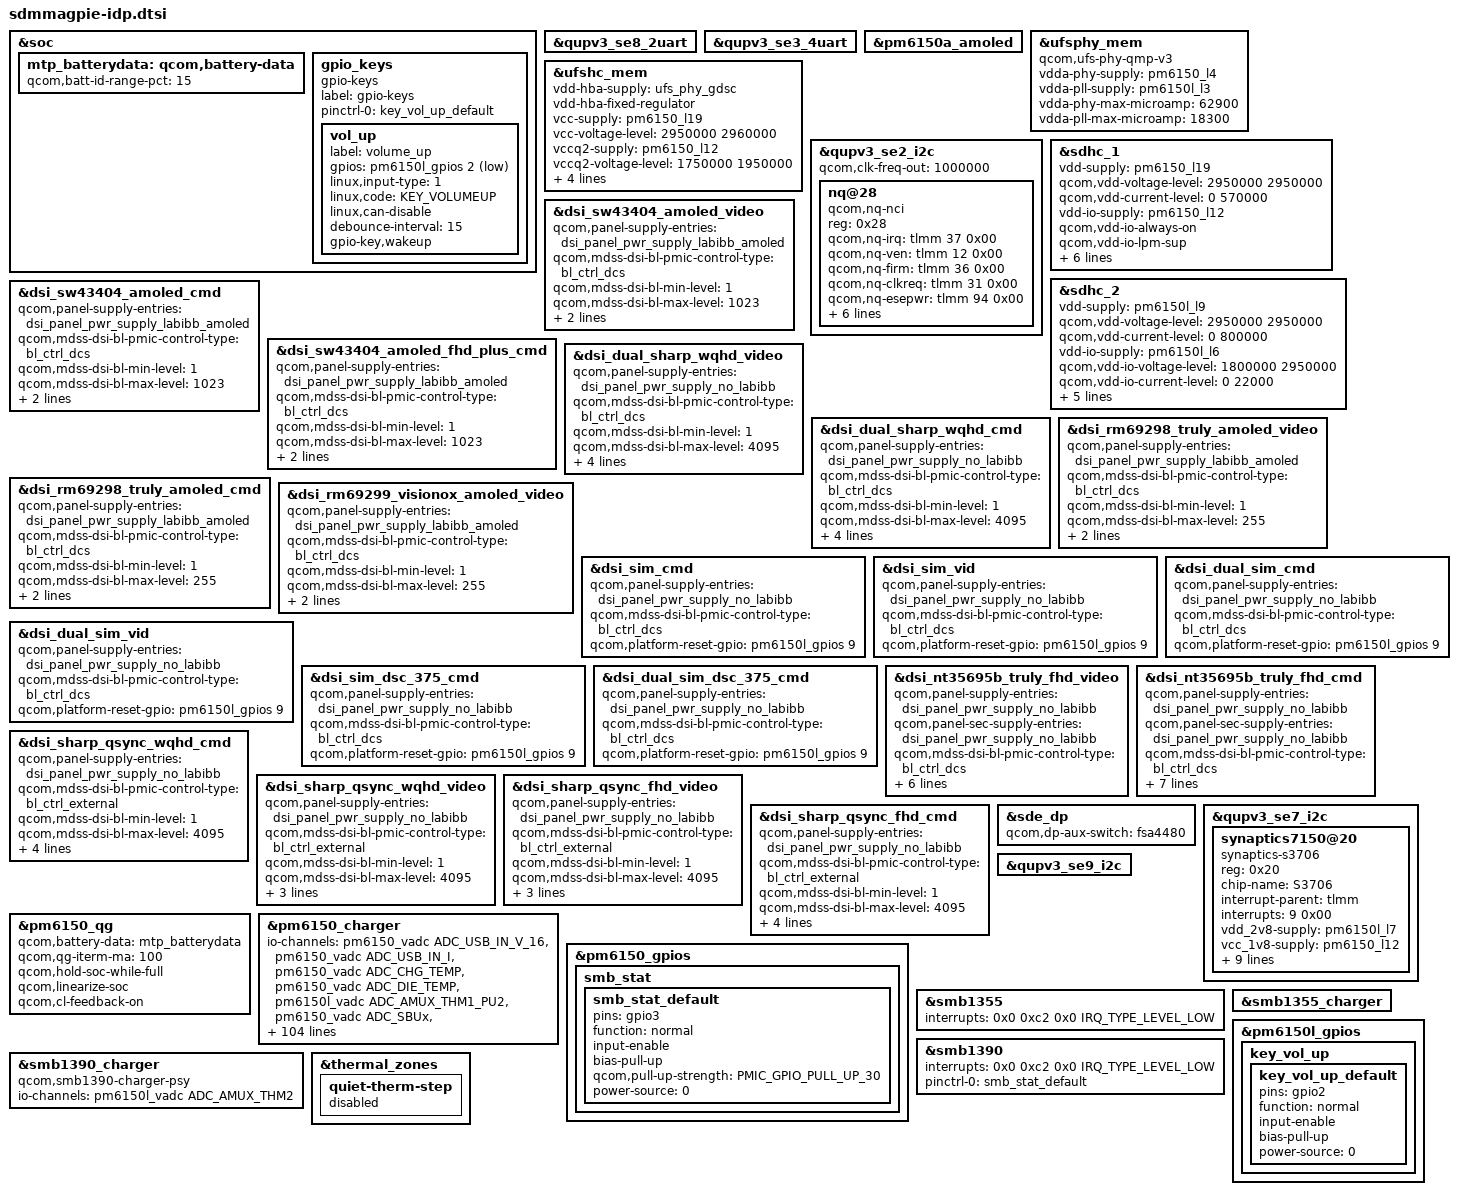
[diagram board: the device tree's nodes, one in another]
/* Copyright (c) 2018-2019, The Linux Foundation. All rights reserved.
 *
 * This program is free software; you can redistribute it and/or modify
 * it under the terms of the GNU General Public License version 2 and
 * only version 2 as published by the Free Software Foundation.
 *
 * This program is distributed in the hope that it will be useful,
 * but WITHOUT ANY WARRANTY; without even the implied warranty of
 * MERCHANTABILITY or FITNESS FOR A PARTICULAR PURPOSE.  See the
 * GNU General Public License for more details.
 */
#include "sdmmagpie-thermal-overlay.dtsi"

#include <dt-bindings/gpio/gpio.h>
#include <dt-bindings/pinctrl/qcom,pmic-gpio.h>
#include <dt-bindings/iio/qcom,spmi-vadc.h>
#include <dt-bindings/input/input.h>
#include "sdmmagpie-sde-display.dtsi"
#include "sdmmagpie-camera-sensor-idp.dtsi"

&soc {
	mtp_batterydata: qcom,battery-data {
		qcom,batt-id-range-pct = <15>;
		#include "qg-batterydata-alium-3600mah.dtsi"
		#include "qg-batterydata-mlp466076-3200mah.dtsi"
	};
};

&qupv3_se8_2uart {
	status = "ok";
};

&qupv3_se3_4uart {
	status = "ok";
};

&pm6150a_amoled {
	status = "ok";
};

&ufsphy_mem {
	compatible = "qcom,ufs-phy-qmp-v3";

	vdda-phy-supply = <&pm6150_l4>; /* 0.88v */
	vdda-pll-supply = <&pm6150l_l3>; /* 1.2v */
	vdda-phy-max-microamp = <62900>;
	vdda-pll-max-microamp = <18300>;

	status = "ok";
};

&ufshc_mem {
	vdd-hba-supply = <&ufs_phy_gdsc>;
	vdd-hba-fixed-regulator;
	vcc-supply = <&pm6150_l19>;
	vcc-voltage-level = <2950000 2960000>;
	vccq2-supply = <&pm6150_l12>;
	vccq2-voltage-level = <1750000 1950000>;
	vcc-max-microamp = <600000>;
	vccq2-max-microamp = <600000>;

	qcom,vddp-ref-clk-supply = <&pm6150l_l3>;
	qcom,vddp-ref-clk-max-microamp = <100>;

	status = "ok";
};

&qupv3_se2_i2c {
	status = "ok";
	qcom,clk-freq-out = <1000000>;
	nq@28 {
		compatible = "qcom,nq-nci";
		reg = <0x28>;
		qcom,nq-irq = <&tlmm 37 0x00>;
		qcom,nq-ven = <&tlmm 12 0x00>;
		qcom,nq-firm = <&tlmm 36 0x00>;
		qcom,nq-clkreq = <&tlmm 31 0x00>;
		qcom,nq-esepwr = <&tlmm 94 0x00>;
		interrupt-parent = <&tlmm>;
		interrupts = <37 0>;
		interrupt-names = "nfc_irq";
		pinctrl-names = "nfc_active", "nfc_suspend";
		pinctrl-0 = <&nfc_int_active &nfc_enable_active
				&nfc_clk_req_active>;
		pinctrl-1 = <&nfc_int_suspend &nfc_enable_suspend
				&nfc_clk_req_suspend>;
	};
};

&sdhc_1 {
	vdd-supply = <&pm6150_l19>;
	qcom,vdd-voltage-level = <2950000 2950000>;
	qcom,vdd-current-level = <0 570000>;

	vdd-io-supply = <&pm6150_l12>;
	qcom,vdd-io-always-on;
	qcom,vdd-io-lpm-sup;
	qcom,vdd-io-voltage-level = <1800000 1800000>;
	qcom,vdd-io-current-level = <0 325000>;

	pinctrl-names = "active", "sleep";
	pinctrl-0 = <&sdc1_clk_on &sdc1_cmd_on &sdc1_data_on &sdc1_rclk_on>;
	pinctrl-1 = <&sdc1_clk_off &sdc1_cmd_off &sdc1_data_off &sdc1_rclk_off>;

	status = "ok";
};

&sdhc_2 {
	vdd-supply = <&pm6150l_l9>;
	qcom,vdd-voltage-level = <2950000 2950000>;
	qcom,vdd-current-level = <0 800000>;

	vdd-io-supply = <&pm6150l_l6>;
	qcom,vdd-io-voltage-level = <1800000 2950000>;
	qcom,vdd-io-current-level = <0 22000>;

	pinctrl-names = "active", "sleep";
	pinctrl-0 = <&sdc2_clk_on  &sdc2_cmd_on &sdc2_data_on &sdc2_cd_on>;
	pinctrl-1 = <&sdc2_clk_off &sdc2_cmd_off &sdc2_data_off &sdc2_cd_off>;

	cd-gpios = <&tlmm 69 GPIO_ACTIVE_LOW>;

	status = "ok";
};

&dsi_sw43404_amoled_video {
	qcom,panel-supply-entries = <&dsi_panel_pwr_supply_labibb_amoled>;
	qcom,mdss-dsi-bl-pmic-control-type = "bl_ctrl_dcs";
	qcom,mdss-dsi-bl-min-level = <1>;
	qcom,mdss-dsi-bl-max-level = <1023>;
	qcom,platform-te-gpio = <&tlmm 10 0>;
	qcom,platform-reset-gpio = <&pm6150l_gpios 9 0>;
};

&dsi_sw43404_amoled_cmd {
	qcom,panel-supply-entries = <&dsi_panel_pwr_supply_labibb_amoled>;
	qcom,mdss-dsi-bl-pmic-control-type = "bl_ctrl_dcs";
	qcom,mdss-dsi-bl-min-level = <1>;
	qcom,mdss-dsi-bl-max-level = <1023>;
	qcom,platform-te-gpio = <&tlmm 10 0>;
	qcom,platform-reset-gpio = <&pm6150l_gpios 9 0>;
};

&dsi_sw43404_amoled_fhd_plus_cmd {
	qcom,panel-supply-entries = <&dsi_panel_pwr_supply_labibb_amoled>;
	qcom,mdss-dsi-bl-pmic-control-type = "bl_ctrl_dcs";
	qcom,mdss-dsi-bl-min-level = <1>;
	qcom,mdss-dsi-bl-max-level = <1023>;
	qcom,platform-te-gpio = <&tlmm 10 0>;
	qcom,platform-reset-gpio = <&pm6150l_gpios 9 0>;
};

&dsi_dual_sharp_wqhd_video {
	qcom,panel-supply-entries = <&dsi_panel_pwr_supply_no_labibb>;
	qcom,mdss-dsi-bl-pmic-control-type = "bl_ctrl_dcs";
	qcom,mdss-dsi-bl-min-level = <1>;
	qcom,mdss-dsi-bl-max-level = <4095>;
	qcom,platform-te-gpio = <&tlmm 10 0>;
	qcom,platform-reset-gpio = <&pm6150l_gpios 9 0>;
	qcom,platform-en-gpio = <&pm6150l_gpios 4 0>;
	qcom,platform-bklight-en-gpio = <&pm6150l_gpios 5 0>;
};

&dsi_dual_sharp_wqhd_cmd {
	qcom,panel-supply-entries = <&dsi_panel_pwr_supply_no_labibb>;
	qcom,mdss-dsi-bl-pmic-control-type = "bl_ctrl_dcs";
	qcom,mdss-dsi-bl-min-level = <1>;
	qcom,mdss-dsi-bl-max-level = <4095>;
	qcom,platform-te-gpio = <&tlmm 10 0>;
	qcom,platform-reset-gpio = <&pm6150l_gpios 9 0>;
	qcom,platform-en-gpio = <&pm6150l_gpios 4 0>;
	qcom,platform-bklight-en-gpio = <&pm6150l_gpios 5 0>;
};

&dsi_rm69298_truly_amoled_video {
	qcom,panel-supply-entries = <&dsi_panel_pwr_supply_labibb_amoled>;
	qcom,mdss-dsi-bl-pmic-control-type = "bl_ctrl_dcs";
	qcom,mdss-dsi-bl-min-level = <1>;
	qcom,mdss-dsi-bl-max-level = <255>;
	qcom,platform-te-gpio = <&tlmm 10 0>;
	qcom,platform-reset-gpio = <&pm6150l_gpios 9 0>;
};

&dsi_rm69298_truly_amoled_cmd {
	qcom,panel-supply-entries = <&dsi_panel_pwr_supply_labibb_amoled>;
	qcom,mdss-dsi-bl-pmic-control-type = "bl_ctrl_dcs";
	qcom,mdss-dsi-bl-min-level = <1>;
	qcom,mdss-dsi-bl-max-level = <255>;
	qcom,platform-te-gpio = <&tlmm 10 0>;
	qcom,platform-reset-gpio = <&pm6150l_gpios 9 0>;
};

&dsi_rm69299_visionox_amoled_video {
	qcom,panel-supply-entries = <&dsi_panel_pwr_supply_labibb_amoled>;
	qcom,mdss-dsi-bl-pmic-control-type = "bl_ctrl_dcs";
	qcom,mdss-dsi-bl-min-level = <1>;
	qcom,mdss-dsi-bl-max-level = <255>;
	qcom,platform-te-gpio = <&tlmm 10 0>;
	qcom,platform-reset-gpio = <&pm6150l_gpios 9 0>;
};

&dsi_sim_cmd {
	qcom,panel-supply-entries = <&dsi_panel_pwr_supply_no_labibb>;
	qcom,mdss-dsi-bl-pmic-control-type = "bl_ctrl_dcs";
	qcom,platform-reset-gpio = <&pm6150l_gpios 9 0>;
};

&dsi_sim_vid {
	qcom,panel-supply-entries = <&dsi_panel_pwr_supply_no_labibb>;
	qcom,mdss-dsi-bl-pmic-control-type = "bl_ctrl_dcs";
	qcom,platform-reset-gpio = <&pm6150l_gpios 9 0>;
};

&dsi_dual_sim_cmd {
	qcom,panel-supply-entries = <&dsi_panel_pwr_supply_no_labibb>;
	qcom,mdss-dsi-bl-pmic-control-type = "bl_ctrl_dcs";
	qcom,platform-reset-gpio = <&pm6150l_gpios 9 0>;
};

&dsi_dual_sim_vid {
	qcom,panel-supply-entries = <&dsi_panel_pwr_supply_no_labibb>;
	qcom,mdss-dsi-bl-pmic-control-type = "bl_ctrl_dcs";
	qcom,platform-reset-gpio = <&pm6150l_gpios 9 0>;
};

&dsi_sim_dsc_375_cmd {
	qcom,panel-supply-entries = <&dsi_panel_pwr_supply_no_labibb>;
	qcom,mdss-dsi-bl-pmic-control-type = "bl_ctrl_dcs";
	qcom,platform-reset-gpio = <&pm6150l_gpios 9 0>;
};

&dsi_dual_sim_dsc_375_cmd {
	qcom,panel-supply-entries = <&dsi_panel_pwr_supply_no_labibb>;
	qcom,mdss-dsi-bl-pmic-control-type = "bl_ctrl_dcs";
	qcom,platform-reset-gpio = <&pm6150l_gpios 9 0>;
};

&dsi_nt35695b_truly_fhd_video {
	qcom,panel-supply-entries = <&dsi_panel_pwr_supply_no_labibb>;
	qcom,panel-sec-supply-entries = <&dsi_panel_pwr_supply_no_labibb>;
	qcom,mdss-dsi-bl-pmic-control-type = "bl_ctrl_dcs";
	qcom,mdss-dsi-sec-bl-pmic-control-type = "bl_ctrl_dcs";
	qcom,platform-reset-gpio = <&pm6150l_gpios 11 0>;
	qcom,platform-sec-reset-gpio = <&pm6150l_gpios 11 0>;
	qcom,platform-en-gpio = <&pm6150l_gpios 4 0>;
	qcom,platform-bklight-en-gpio = <&pm6150l_gpios 5 0>;
};

&dsi_nt35695b_truly_fhd_cmd {
	qcom,panel-supply-entries = <&dsi_panel_pwr_supply_no_labibb>;
	qcom,panel-sec-supply-entries = <&dsi_panel_pwr_supply_no_labibb>;
	qcom,mdss-dsi-bl-pmic-control-type = "bl_ctrl_dcs";
	qcom,mdss-dsi-sec-bl-pmic-control-type = "bl_ctrl_dcs";
	qcom,platform-reset-gpio = <&pm6150l_gpios 11 0>;
	qcom,platform-sec-reset-gpio = <&pm6150l_gpios 11 0>;
	qcom,platform-en-gpio = <&pm6150l_gpios 4 0>;
	qcom,platform-bklight-en-gpio = <&pm6150l_gpios 5 0>;
	qcom,platform-te-gpio = <&tlmm 11 0>;
};

&dsi_sharp_qsync_wqhd_cmd {
	qcom,panel-supply-entries = <&dsi_panel_pwr_supply_no_labibb>;
	qcom,mdss-dsi-bl-pmic-control-type = "bl_ctrl_external";
	qcom,mdss-dsi-bl-min-level = <1>;
	qcom,mdss-dsi-bl-max-level = <4095>;
	qcom,platform-te-gpio = <&tlmm 10 0>;
	qcom,platform-reset-gpio = <&pm6150l_gpios 9 0>;
	qcom,platform-en-gpio = <&pm6150l_gpios 4 0>;
	qcom,platform-bklight-en-gpio = <&pm6150l_gpios 5 0>;
};

&dsi_sharp_qsync_wqhd_video {
	qcom,panel-supply-entries = <&dsi_panel_pwr_supply_no_labibb>;
	qcom,mdss-dsi-bl-pmic-control-type = "bl_ctrl_external";
	qcom,mdss-dsi-bl-min-level = <1>;
	qcom,mdss-dsi-bl-max-level = <4095>;
	qcom,platform-reset-gpio = <&pm6150l_gpios 9 0>;
	qcom,platform-en-gpio = <&pm6150l_gpios 4 0>;
	qcom,platform-bklight-en-gpio = <&pm6150l_gpios 5 0>;
};

&dsi_sharp_qsync_fhd_video {
	qcom,panel-supply-entries = <&dsi_panel_pwr_supply_no_labibb>;
	qcom,mdss-dsi-bl-pmic-control-type = "bl_ctrl_external";
	qcom,mdss-dsi-bl-min-level = <1>;
	qcom,mdss-dsi-bl-max-level = <4095>;
	qcom,platform-reset-gpio = <&pm6150l_gpios 9 0>;
	qcom,platform-en-gpio = <&pm6150l_gpios 4 0>;
	qcom,platform-bklight-en-gpio = <&pm6150l_gpios 5 0>;
};

&dsi_sharp_qsync_fhd_cmd {
	qcom,panel-supply-entries = <&dsi_panel_pwr_supply_no_labibb>;
	qcom,mdss-dsi-bl-pmic-control-type = "bl_ctrl_external";
	qcom,mdss-dsi-bl-min-level = <1>;
	qcom,mdss-dsi-bl-max-level = <4095>;
	qcom,platform-te-gpio = <&tlmm 10 0>;
	qcom,platform-reset-gpio = <&pm6150l_gpios 9 0>;
	qcom,platform-en-gpio = <&pm6150l_gpios 4 0>;
	qcom,platform-bklight-en-gpio = <&pm6150l_gpios 5 0>;
};

&sde_dp {
	qcom,dp-aux-switch = <&fsa4480>;
};

&qupv3_se7_i2c {
//#ifndef VENDOR_EDIT
//ZhongWenjie@BSP.group 2019-03-29 add for enable tp function
//	qcom,i2c-touch-active="st,fts";
//#endif
	status = "ok";
//#ifndef VENDOR_EDIT
//ZhongWenjie@BSP.group 2019-03-29 add for enable tp function
/*
	st_fts@49 {
		compatible = "st,fts";
		reg = <0x49>;
		interrupt-parent = <&tlmm>;
		interrupts = <9 0x2008>;
		vdd-supply = <&pm6150_l10>;
		avdd-supply = <&pm6150l_l7>;
		pinctrl-names = "pmx_ts_active", "pmx_ts_suspend",
					"pmx_ts_release";
		pinctrl-0 = <&ts_active>;
		pinctrl-1 = <&ts_int_suspend &ts_reset_suspend>;
		pinctrl-2 = <&ts_release>;
		st,irq-gpio = <&tlmm 9 0x2008>;
		st,reset-gpio = <&tlmm 8 0x00>;
		st,regulator_dvdd = "vdd";
		st,regulator_avdd = "avdd";
		st,x-flip;
		st,y-flip;
	};

	synaptics_dsx@20 {
		compatible = "synaptics,dsx-i2c";
		reg = <0x20>;
		interrupt-parent = <&tlmm>;
		interrupts = <9 0x2008>;
		vdd-supply = <&pm6150_l10>;
		avdd-supply = <&pm6150l_l7>;
		pinctrl-names = "pmx_ts_active","pmx_ts_suspend",
					"pmx_ts_release";
		pinctrl-0 = <&ts_active>;
		pinctrl-1 = <&ts_int_suspend &ts_reset_suspend>;
		pinctrl-2 = <&ts_release>;
		synaptics,pwr-reg-name = "avdd";
		synaptics,bus-reg-name = "vdd";
		synaptics,ub-i2c-addr = <0x20>;
		synaptics,max-y-for-2d = <2159>;
		synaptics,irq-gpio = <&tlmm 9 0x2008>;
		synaptics,reset-gpio = <&tlmm 8 0x0>;
		synaptics,irq-on-state = <0>;
		synaptics,power-delay-ms = <200>;
		synaptics,reset-delay-ms = <200>;
		synaptics,reset-on-state = <0>;
		synaptics,reset-active-ms = <20>;
	};
*/
//#else
	synaptics7150@20 {
		compatible = "synaptics-s3706";
		reg = <0x20>;
		chip-name = "S3706";

		interrupt-parent = <&tlmm>;
		interrupts = <9 0x00>;
		vdd_2v8-supply = <&pm6150l_l7>;
		vcc_1v8-supply = <&pm6150_l12>;
		irq-gpio = <&tlmm 9 0x2008>;
		reset-gpio = <&tlmm 8 0x1>;
		pinctrl-names = "default";
		pinctrl-0 = <&ts_int_active &ts_reset_active>;

		touchpanel,max-num-support = <10>;
		touchpanel,tx-rx-num = <16 33>;
		touchpanel,panel-coords = <1080 2340>;
		touchpanel,display-coords = <1080 2340>;

		//external_touch_support;

		touchpanel,button-type = <4>;
		touchpanel.button-TRx = <0 0>;
	};
//#endif
};

&pm6150_qg {
	qcom,battery-data = <&mtp_batterydata>;
	qcom,qg-iterm-ma = <100>;
	qcom,hold-soc-while-full;
	qcom,linearize-soc;
	qcom,cl-feedback-on;
};

&pm6150_charger {
	io-channels = <&pm6150_vadc ADC_USB_IN_V_16>,
		      <&pm6150_vadc ADC_USB_IN_I>,
		      <&pm6150_vadc ADC_CHG_TEMP>,
		      <&pm6150_vadc ADC_DIE_TEMP>,
		      <&pm6150l_vadc ADC_AMUX_THM1_PU2>,
		      <&pm6150_vadc ADC_SBUx>,
		      <&pm6150_vadc ADC_VPH_PWR>;
	io-channel-names = "usb_in_voltage",
			   "usb_in_current",
			   "chg_temp",
			   "die_temp",
			   "conn_temp",
			   "sbux_res",
			   "vph_voltage";
	qcom,battery-data = <&mtp_batterydata>;
	qcom,auto-recharge-soc = <98>;
	qcom,step-charging-enable;
	qcom,sw-jeita-enable;
	qcom,fcc-stepping-enable;
	qcom,suspend-input-on-debug-batt;
	qcom,sec-charger-config = <3>;
	qcom,thermal-mitigation = <4200000 3500000 3000000
			2500000 2000000 1500000 1000000 500000>;
	dpdm-supply = <&qusb_phy0>;

	qcom,charger-temp-max = <800>;
	qcom,smb-temp-max = <800>;

//#ifdef VENDOR_EDIT
/* Yichun.Chen  PSW.BSP.CHG  2019-04-08  for charge */
	qcom,usb-icl-ua = <2000000>;
	qcom,fcc-max-ua = <2000000>;
	//qcom,fv-max-uv = <4373000>;
	qcom,hvdcp-disable;
//	qcom,pm660chg-vadc = <&pm660_vadc>;//chargID
//	qcom,pm660usbtemp-vadc = <&pm660_vadc>;//usb temp
	//qcom,otg-cl-ua = <2000000>;
	qcom,float-option = <1>;

	//for oppo chg framework:
	qcom,input_current_charger_ma = <2000>;
	qcom,input_current_usb_ma = <500>;

	qcom,input_current_led_ma = <1200>;

	qcom,input_current_camera_ma = <1200>;
	//qcom,input_current_led_ma_overtemp = <900>;
	qcom,overtemp_bat_decidegc = <350>;
	qcom,iterm_disabled = <0>;
	qcom,iterm_ma = <170>;
	qcom,recharge-mv = <100>;
	qcom,batt_capacity_mah = <3415>;

	qcom,removed_bat_decidegc = <190>;  /*<-19C*/

	qcom,cold_bat_decidegc = <30>;  /*-3C~0C*/
	qcom,temp_cold_vfloat_mv = <3980>;
	qcom,temp_cold_fastchg_current_ma = <330>;

	qcom,little_cold_bat_decidegc = <0>;	/*0C~5C*/
	qcom,temp_little_cold_vfloat_mv = <4373>;
	qcom,temp_little_cold_fastchg_current_ma = <510>;

	qcom,cool_bat_decidegc = <50>;	/*5C~12C*/
	qcom,temp_cool_vfloat_mv = <4373>;
	qcom,temp_cool_fastchg_current_ma_high = <850>;
	qcom,temp_cool_fastchg_current_ma_low = <510>;

	qcom,little_cool_bat_decidegc = <120>;	/*12C~16C*/
	qcom,temp_little_cool_vfloat_mv = <4373>;
	qcom,temp_little_cool_fastchg_current_ma = <1530>;

	qcom,normal_bat_decidegc = <160>;	/*16C~45C*/
	qcom,temp_normal_fastchg_current_ma = <2000>;
	qcom,temp_normal_vfloat_mv = <4373>;

	qcom,warm_bat_decidegc = <480>;		/*48C~53C*/ /*8pin Bat Vooc project need add 3 degree C*/
	qcom,temp_warm_vfloat_mv = <4080>;
	qcom,temp_warm_fastchg_current_ma = <850>;

	qcom,hot_bat_decidegc = <530>;

	qcom,non_standard_vfloat_mv = <3980>;
	qcom,non_standard_fastchg_current_ma = <512>;

	qcom,short_c_bat_cv_mv = <4330>;
	qcom,short_c_bat_vfloat_mv = <3800>;
	qcom,short_c_bat_fastchg_current_ma = <512>;

	qcom,cold_vfloat_sw_limit = <3930>;
	qcom,little_cold_vfloat_sw_limit = <4320>;
	qcom,cool_vfloat_sw_limit = <4320>;
	qcom,little_cool_vfloat_sw_limit = <4320>;
	qcom,normal_vfloat_sw_limit = <4320>;
	qcom,warm_vfloat_sw_limit = <4030>;
	qcom,non_standard_vfloat_sw_limit = <3930>;
	qcom,short_c_bat_vfloat_sw_limit = <3750>;

	qcom,max_chg_time_sec = <36000>;
	qcom,charger_hv_thr = <5800>;
	qcom,charger_lv_thr = <3400>;
	qcom,vbatt_full_thr = <4400>;
	qcom,vbatt_hv_thr = <4500>;
	qcom,vfloat_step_mv = <8>;
	qcom,non_standard_vfloat_over_sw_limit = <3990>;
	qcom,cold_vfloat_over_sw_limit = <3990>;
	qcom,little_cold_vfloat_over_sw_limit = <4385>;
	qcom,cool_vfloat_over_sw_limit = <4385>;
	qcom,little_cool_vfloat_over_sw_limit = <4385>;
	qcom,normal_vfloat_over_sw_limit = <4385>;
	qcom,warm_vfloat_over_sw_limit = <4090>;

	qcom,vbatt_power_off = <3300>;
	qcom,vbatt_soc_1 = <3410>;
	qcom,vooc_project = <1>;
	qcom,vbatt_num = <1>;

	qcom,normal_vterm_hw_inc = <18>;
	qcom,non_normal_vterm_hw_inc = <18>;
	
	qcom,overchg_normal_fastchg_ma = <700>;/*16C~35c*/
	qcom,overchg_temp_warm_decidegc = <350>;
	qcom,overchg_warm_fastchg_ma = <750>;/*35C~40c*/			
	qcom,overchg_temp_high_decidegc = <400>;
	
	qcom,overchg_normal_vfloat_sw_limit = <4450>;
	qcom,overchg_temp_normal_vfloat_mv = <4500>;
	qcom,overchg_normal_vfloat_over_sw_limit = <4500>;
	
	qcom,default_iterm_ma = <170>;			
	qcom,default_temp_normal_fastchg_current_ma = <2000>;			
	qcom,default_normal_vfloat_sw_limit = <4320>;
	qcom,default_temp_normal_vfloat_mv = <4373>;
	qcom,default_normal_vfloat_over_sw_limit = <4385>;
	
	///qcom,offset_temp = <30>;
	//for control:
	//qcom,suspend_after_full;
	qcom,check_batt_full_by_sw;
	qcom,external_gauge;
	qcom,chg_ctrl_by_lcd;
	qcom,chg_ctrl_by_camera;
	qcom,sw_vfloat_over_protect_enable;

	qcom,chargerid_switch-gpio = <&pm6150_gpios 1 0x00>;
	qcom,ship-gpio = <&tlmm 11 0x00>;
	//qcom,shortc-gpio = <&tlmm 43 0x00>;
	//qcom,ccdetect-gpio = <&tlmm 40 0x00>;
	//qcom,dischg-gpio = <&pm660l_gpios 7 0x00>;
	pinctrl-names = "chargerid_switch_active", "chargerid_switch_sleep", "chargerid_switch_default",
			"ship_active", "ship_sleep";
	pinctrl-0 = <&chargerid_switch_active>;
	pinctrl-1 = <&chargerid_switch_sleep>;
	pinctrl-2 = <&chargerid_switch_default>;
	pinctrl-3 = <&ship_active>;
	pinctrl-4 = <&ship_sleep>;
//#endif
};

&pm6150_gpios {
	smb_stat {
		smb_stat_default: smb_stat_default {
			pins = "gpio3";
			function = "normal";
			input-enable;
			bias-pull-up;
			qcom,pull-up-strength = <PMIC_GPIO_PULL_UP_30>;
			power-source = <0>;
		};
	};
};

&qupv3_se9_i2c {
	status = "ok";
	#include "smb1390.dtsi"
	#include "smb1355.dtsi"
};

&smb1355 {
	/delete-property/ interrupts;
	interrupts = <0x0 0xc2 0x0 IRQ_TYPE_LEVEL_LOW>;
	status = "ok";
};

&smb1355_charger {
	status = "ok";
};

&smb1390 {
	/delete-property/ interrupts;
	interrupts = <0x0 0xc2 0x0 IRQ_TYPE_LEVEL_LOW>;
	pinctrl-names = "default";
	pinctrl-0 = <&smb_stat_default>;
	status = "ok";
};

&smb1390_charger {
	compatible = "qcom,smb1390-charger-psy";
	io-channels = <&pm6150l_vadc ADC_AMUX_THM2>;
	io-channel-names = "cp_die_temp";
	status = "ok";
};

&pm6150l_gpios {
	key_vol_up {
		key_vol_up_default: key_vol_up_default {
			pins = "gpio2";
			function = "normal";
			input-enable;
			bias-pull-up;
			power-source = <0>;
		};
	};
};

&soc {
	gpio_keys {
		compatible = "gpio-keys";
		label = "gpio-keys";

		pinctrl-names = "default";
		pinctrl-0 = <&key_vol_up_default>;

		vol_up {
			label = "volume_up";
			gpios = <&pm6150l_gpios 2 GPIO_ACTIVE_LOW>;
			linux,input-type = <1>;
			linux,code = <KEY_VOLUMEUP>;
			linux,can-disable;
			debounce-interval = <15>;
			gpio-key,wakeup;
		};
	};
};

&thermal_zones {
	quiet-therm-step {
		status = "disabled";
	};
};
